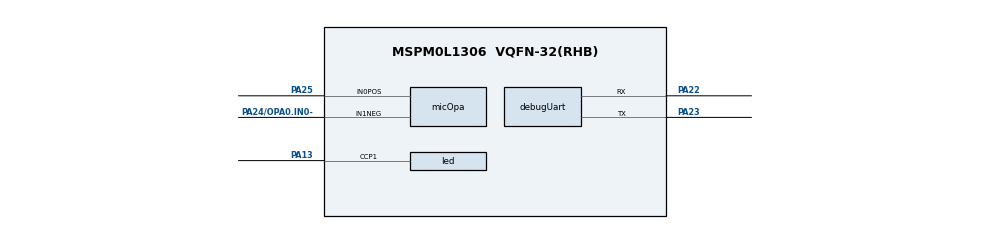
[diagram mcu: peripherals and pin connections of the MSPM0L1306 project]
// @cliArgs --device "MSPM0L130X" --package "VQFN-32(RHB)" --part "Default"
// @v2CliArgs --device "MSPM0L1306" --package "VQFN-32(RHB)"
// @cliArgs --board /ti/boards/LP_MSPM0L1306 --rtos nortos
const Board = scripting.addModule("/ti/driverlib/Board");
const SYSCTL = scripting.addModule("/ti/driverlib/SYSCTL");
SYSCTL.clockTreeEn = true;
const PWM = scripting.addModule("/ti/driverlib/PWM", {}, false);
const led = PWM.addInstance();
led.$name = "LED_PWM";
led.clockSource = "BUSCLK";
led.clockPrescale = 1;
led.timerCount = 4096;
led.pwmMode = "EDGE_ALIGN";
led.ccIndex = [1];
led.PWM_CHANNEL_1.$name = "LED_GREEN";
led.PWM_CHANNEL_1.dutyCycle = 0;
led.peripheral.$assign = "TIMG0";
led.peripheral.ccp1Pin.$assign = "PA13";
const GPIO = scripting.addModule("/ti/driverlib/GPIO", {}, false);
const buttons = GPIO.addInstance();
buttons.$name = "GPIO_BUTTONS";
buttons.associatedPins.create(2);
buttons.associatedPins[0].$name = "PLUS";
buttons.associatedPins[0].assignedPin = "18";
buttons.associatedPins[0].direction = "INPUT";
buttons.associatedPins[1].$name = "MINUS";
buttons.associatedPins[1].assignedPin = "14";
buttons.associatedPins[1].direction = "INPUT";
buttons.associatedPins[1].internalResistor = "PULL_UP";

// A timer event starts one OPA/raw pair. MEM1 waits for the next event.
const TIMER = scripting.addModule("/ti/driverlib/TIMER", {}, false);
const sampleTimer = TIMER.addInstance();
sampleTimer.$name = "AUDIO_TIMER";
sampleTimer.timerClkSrc = "BUSCLK";
sampleTimer.timerMode = "PERIODIC";
sampleTimer.timerPeriod = "62.5 us";
sampleTimer.event1PublisherChannel = 1;
sampleTimer.event1ControllerInterruptEn = ["ZERO_EVENT"];
sampleTimer.peripheral.$assign = "TIMG1";
const OPA = scripting.addModule("/ti/driverlib/OPA", {}, false);
const micOpa = OPA.addInstance();
micOpa.$name = "MIC_OPA";
micOpa.cfg0PSELChannel = "IN0_POS";
micOpa.cfg0NSELChannel = "RTAP";
micOpa.cfg0MSELChannel = "IN1_NEG";
micOpa.cfg0Gain = "N15_P16";
micOpa.cfg0OutputPin = "DISABLED";
micOpa.advBW = "LOW";
micOpa.peripheral.$assign = "OPA0";
micOpa.peripheral.In0PosPin.$assign = "PA25";
micOpa.peripheral.In1NegPin.$assign = "PA24/OPA0.IN0-";
const VREF = scripting.addModule("/ti/driverlib/VREF");
VREF.basicIntVolt = "DL_VREF_BUFCONFIG_OUTPUT_2_5V";
VREF.advClockConfigEnable = true;
VREF.advClkSrc = "DL_VREF_CLOCK_BUSCLK";
const ADC12 = scripting.addModule("/ti/driverlib/ADC12", {}, false);
const adc = ADC12.addInstance();
adc.$name = "AUDIO_ADC";
adc.sampClkSrc = "DL_ADC12_CLOCK_ULPCLK";
adc.sampClkDiv = "DL_ADC12_CLOCK_DIVIDE_8";
adc.samplingOperationMode = "sequence";
adc.repeatMode = true;
adc.endAdd = 1;
adc.adcMem0chansel = "DL_ADC12_INPUT_CHAN_12";
adc.adcMem1chansel = "DL_ADC12_INPUT_CHAN_9";
adc.adcMem0trig = "DL_ADC12_TRIGGER_MODE_AUTO_NEXT";
adc.adcMem1trig = "DL_ADC12_TRIGGER_MODE_TRIGGER_NEXT";
adc.adcMem1stime = "DL_ADC12_SAMPLE_TIMER_SOURCE_SCOMP1";
adc.adcMem0vref = "VREF";
adc.adcMem1vref = "VREF";
adc.adcMem0vrefDependencySelect = "DL_ADC12_REFERENCE_VOLTAGE_INTREF";
adc.adcMem1vrefDependencySelect = "DL_ADC12_REFERENCE_VOLTAGE_INTREF";
adc.sampleTime0 = "5 us";
adc.sampleTime1 = "10 us";
adc.powerDownMode = "DL_ADC12_POWER_DOWN_MODE_MANUAL";
adc.subChanID = 1;
adc.trigSrc = "DL_ADC12_TRIG_SRC_EVENT";
adc.enableFIFO = true;
adc.configureDMA = true;
adc.sampCnt = 1;
// The four-entry FIFO alternates packed words between MEM1 and MEM3.
adc.enabledDMATriggers = ["DL_ADC12_DMA_MEM1_RESULT_LOADED", "DL_ADC12_DMA_MEM3_RESULT_LOADED"];
adc.enabledInterrupts = ["DL_ADC12_INTERRUPT_OVERFLOW", "DL_ADC12_INTERRUPT_TRIG_OVF"];
adc.peripheral.$assign = "ADC0";
adc.peripheral.adcPin9.$assign = "PA15";
adc.DMA_CHANNEL.$name = "AUDIO_DMA";
adc.DMA_CHANNEL.addressMode = "f2b";

// Application diagnostics share the factory BSL UART wires.
const UART = scripting.addModule("/ti/driverlib/UART", {}, false);
const debugUart = UART.addInstance();
debugUart.$name = "DEBUG_UART";
debugUart.targetBaudRate = 115200;
debugUart.enableFIFO = true;
debugUart.peripheral.$assign = "UART0";
debugUart.peripheral.txPin.$assign = "PA23";
debugUart.peripheral.rxPin.$assign = "PA22";
